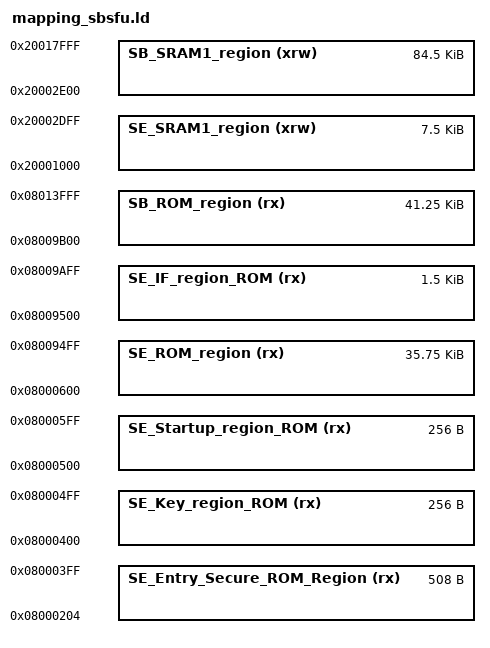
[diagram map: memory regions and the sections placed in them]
/*
*****************************************************************************
**

**  File        : LinkerScript.ld
**
**  Abstract    : Linker script for STM32L475VGTx Device with
**                1024KByte FLASH, 96KByte RAM
**
**                Set heap size, stack size and stack location according
**                to application requirements.
**
**                Set memory bank area and size if external memory is used.
**
**  Target      : STMicroelectronics STM32
**
**
**  Distribution: The file is distributed as is, without any warranty
**                of any kind.
**
**  (c)Copyright Ac6.
**  You may use this file as-is or modify it according to the needs of your
**  project. Distribution of this file (unmodified or modified) is not
**  permitted. Ac6 permit registered System Workbench for MCU users the
**  rights to distribute the assembled, compiled & linked contents of this
**  file as part of an application binary file, provided that it is built
**  using the System Workbench for MCU toolchain.
**
*****************************************************************************
*/


/* SE Code region protected by firewall */
VECTOR_SIZE = 0x200;
__ICFEDIT_SE_Code_region_ROM_start__       = 0x08000000 + VECTOR_SIZE;
__ICFEDIT_SE_CallGate_region_ROM_start__   = __ICFEDIT_SE_Code_region_ROM_start__ + 0x4;
__ICFEDIT_SE_CallGate_region_ROM_end__     = __ICFEDIT_SE_Code_region_ROM_start__ + 0x1FF;

/* SE key region protected by firewall */
__ICFEDIT_SE_Key_region_ROM_start__        = __ICFEDIT_SE_CallGate_region_ROM_end__ + 0x1;
__ICFEDIT_SE_Key_region_ROM_end__          = __ICFEDIT_SE_Key_region_ROM_start__ + 0xFF;

/* SE Startup: call before enabling firewall*/
__ICFEDIT_SE_Startup_region_ROM_start__    = __ICFEDIT_SE_Key_region_ROM_end__ + 0x1;
__ICFEDIT_SE_Code_nokey_region_ROM_start__ = __ICFEDIT_SE_Startup_region_ROM_start__ + 0x100;
__ICFEDIT_SE_Code_region_ROM_end__         = __ICFEDIT_SE_Startup_region_ROM_start__ + 0x8FFF;

/* SE IF ROM: used to locate Secure Engine interface code out of firewall */
__ICFEDIT_SE_IF_region_ROM_start__         = __ICFEDIT_SE_Code_region_ROM_end__ + 1;
__ICFEDIT_SE_IF_region_ROM_end__           = __ICFEDIT_SE_IF_region_ROM_start__ + 0x5FF;

/* SBSFU Code region */
__ICFEDIT_SB_region_ROM_start__            = __ICFEDIT_SE_IF_region_ROM_end__ + 0x1;
__ICFEDIT_SB_region_ROM_end__              = 0x08013FFF;

SE_Entry_Secure_ROM_Region_Length = __ICFEDIT_SE_CallGate_region_ROM_end__ - __ICFEDIT_SE_CallGate_region_ROM_start__ + 1;
SE_Key_region_ROM_Length          = __ICFEDIT_SE_Key_region_ROM_end__ - __ICFEDIT_SE_Key_region_ROM_start__ + 1;
SE_Startup_region_ROM_Length      = __ICFEDIT_SE_Code_nokey_region_ROM_start__ - __ICFEDIT_SE_Startup_region_ROM_start__ ;
SE_ROM_region_Length              = __ICFEDIT_SE_Code_region_ROM_end__ - __ICFEDIT_SE_Code_nokey_region_ROM_start__ + 1;
SE_IF_region_ROM_Length           = __ICFEDIT_SE_IF_region_ROM_end__ - __ICFEDIT_SE_IF_region_ROM_start__ + 1;
SB_ROM_region_Length              = __ICFEDIT_SB_region_ROM_end__ - __ICFEDIT_SB_region_ROM_start__ + 1;

/* RAM section */
/* SE RAM1 region protected by firewall */
/* SE stack is placed 1st in RAM, stack overflow does not write on other RAM area */
__ICFEDIT_SE_region_SRAM1_start__     = 0x20000000;
__ICFEDIT_SE_region_SRAM1_stack_top__ = 0x20001000;
__ICFEDIT_SE_region_SRAM1_end__       = 0x20002DFF;

/* SBSFU RAM1 region */
__ICFEDIT_SB_region_SRAM1_start__     = __ICFEDIT_SE_region_SRAM1_end__ + 0x1;
__ICFEDIT_SB_region_SRAM1_end__       = 0x20017FFF;

SE_SRAM1_region_Length = __ICFEDIT_SE_region_SRAM1_end__ - __ICFEDIT_SE_region_SRAM1_stack_top__ + 1;
SB_SRAM1_region_Length = __ICFEDIT_SB_region_SRAM1_end__ - __ICFEDIT_SB_region_SRAM1_start__ + 1;

MEMORY
{
 SE_Entry_Secure_ROM_Region (rx)     : ORIGIN = __ICFEDIT_SE_CallGate_region_ROM_start__, LENGTH = SE_Entry_Secure_ROM_Region_Length
 SE_Key_region_ROM (rx)              : ORIGIN = __ICFEDIT_SE_Key_region_ROM_start__, LENGTH = SE_Key_region_ROM_Length
 SE_Startup_region_ROM (rx)          : ORIGIN = __ICFEDIT_SE_Startup_region_ROM_start__, LENGTH = SE_Startup_region_ROM_Length
 SE_ROM_region (rx)                  : ORIGIN = __ICFEDIT_SE_Code_nokey_region_ROM_start__, LENGTH = SE_ROM_region_Length
 SE_IF_region_ROM (rx)               : ORIGIN = __ICFEDIT_SE_IF_region_ROM_start__, LENGTH = SE_IF_region_ROM_Length
 SB_ROM_region (rx)                  : ORIGIN = __ICFEDIT_SB_region_ROM_start__, LENGTH = SB_ROM_region_Length
 SE_SRAM1_region (xrw)               : ORIGIN = __ICFEDIT_SE_region_SRAM1_stack_top__, LENGTH = SE_SRAM1_region_Length
 SB_SRAM1_region (xrw)               : ORIGIN = __ICFEDIT_SB_region_SRAM1_start__, LENGTH = SB_SRAM1_region_Length
}

